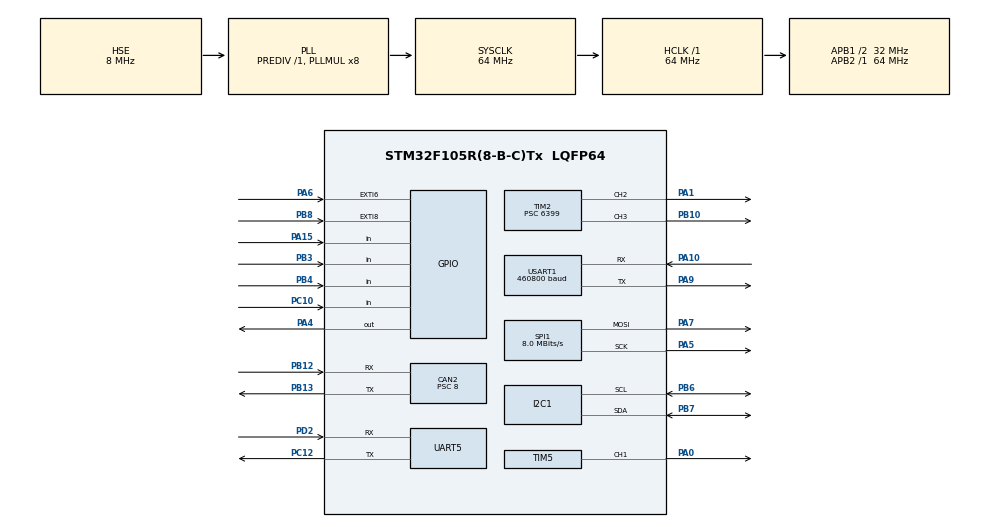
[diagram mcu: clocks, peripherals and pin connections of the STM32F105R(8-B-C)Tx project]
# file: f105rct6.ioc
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CAN2.ABOM=ENABLE
CAN2.BS1=CAN_BS1_13TQ
CAN2.BS2=CAN_BS2_2TQ
CAN2.CalculateBaudRate=250000
CAN2.CalculateTimeBit=4000
CAN2.CalculateTimeQuantum=250.0
CAN2.NART=ENABLE
CAN2.Prescaler=8
Dma.I2C1_RX.0.Direction=DMA_PERIPH_TO_MEMORY
Dma.I2C1_RX.0.Instance=DMA1_Channel7
Dma.I2C1_RX.0.MemDataAlignment=DMA_MDATAALIGN_BYTE
Dma.I2C1_RX.0.MemInc=DMA_MINC_ENABLE
Dma.I2C1_RX.0.Mode=DMA_NORMAL
Dma.I2C1_RX.0.PeriphDataAlignment=DMA_PDATAALIGN_BYTE
Dma.I2C1_RX.0.PeriphInc=DMA_PINC_DISABLE
Dma.I2C1_RX.0.Priority=DMA_PRIORITY_HIGH
Dma.I2C1_TX.1.Direction=DMA_MEMORY_TO_PERIPH
Dma.I2C1_TX.1.Instance=DMA1_Channel6
Dma.I2C1_TX.1.MemDataAlignment=DMA_MDATAALIGN_BYTE
Dma.I2C1_TX.1.MemInc=DMA_MINC_ENABLE
Dma.I2C1_TX.1.Mode=DMA_NORMAL
Dma.I2C1_TX.1.PeriphDataAlignment=DMA_PDATAALIGN_BYTE
Dma.I2C1_TX.1.PeriphInc=DMA_PINC_DISABLE
Dma.I2C1_TX.1.Priority=DMA_PRIORITY_VERY_HIGH
Dma.Request0=I2C1_RX
Dma.Request1=I2C1_TX
Dma.Request2=SPI1_TX
Dma.Request3=USART1_TX
Dma.Request4=USART1_RX
Dma.SPI1_TX.2.Direction=DMA_MEMORY_TO_PERIPH
Dma.SPI1_TX.2.Instance=DMA1_Channel3
Dma.SPI1_TX.2.MemDataAlignment=DMA_MDATAALIGN_BYTE
Dma.SPI1_TX.2.MemInc=DMA_MINC_ENABLE
Dma.SPI1_TX.2.Mode=DMA_NORMAL
Dma.SPI1_TX.2.PeriphDataAlignment=DMA_PDATAALIGN_BYTE
Dma.SPI1_TX.2.PeriphInc=DMA_PINC_DISABLE
Dma.SPI1_TX.2.Priority=DMA_PRIORITY_LOW
Dma.USART1_RX.4.Direction=DMA_PERIPH_TO_MEMORY
Dma.USART1_RX.4.Instance=DMA1_Channel5
Dma.USART1_RX.4.MemDataAlignment=DMA_MDATAALIGN_BYTE
Dma.USART1_RX.4.MemInc=DMA_MINC_ENABLE
Dma.USART1_RX.4.Mode=DMA_NORMAL
Dma.USART1_RX.4.PeriphDataAlignment=DMA_PDATAALIGN_BYTE
Dma.USART1_RX.4.PeriphInc=DMA_PINC_DISABLE
Dma.USART1_RX.4.Priority=DMA_PRIORITY_LOW
Dma.USART1_TX.3.Direction=DMA_MEMORY_TO_PERIPH
Dma.USART1_TX.3.Instance=DMA1_Channel4
Dma.USART1_TX.3.MemDataAlignment=DMA_MDATAALIGN_BYTE
Dma.USART1_TX.3.MemInc=DMA_MINC_ENABLE
Dma.USART1_TX.3.Mode=DMA_NORMAL
Dma.USART1_TX.3.PeriphDataAlignment=DMA_PDATAALIGN_BYTE
Dma.USART1_TX.3.PeriphInc=DMA_PINC_DISABLE
Dma.USART1_TX.3.Priority=DMA_PRIORITY_LOW
FREERTOS.Tasks01=defaultTask,24,1024,StartDefaultTask,Default,NULL,Dynamic,NULL,NULL
FREERTOS.configCHECK_FOR_STACK_OVERFLOW=2
FREERTOS.configENABLE_FPU=1
FREERTOS.configTOTAL_HEAP_SIZE=28000
I2C1.I2C_Mode=I2C_Fast
Mcu.Family=STM32F1
Mcu.Name=STM32F105R(8-B-C)Tx
Mcu.Package=LQFP64
NVIC.CAN2_RX0_IRQn=true\:5\:0\:false\:false\:true\:true\:true\:true\:true
NVIC.CAN2_RX1_IRQn=true\:5\:0\:false\:false\:true\:true\:true\:true\:true
NVIC.CAN2_SCE_IRQn=true\:5\:0\:false\:false\:true\:true\:true\:true\:true
NVIC.CAN2_TX_IRQn=true\:5\:0\:false\:false\:true\:true\:true\:true\:true
NVIC.DMA1_Channel3_IRQn=true\:6\:0\:true\:false\:true\:true\:false\:true\:true
NVIC.DMA1_Channel4_IRQn=true\:5\:0\:false\:false\:true\:true\:false\:true\:true
NVIC.DMA1_Channel5_IRQn=true\:5\:0\:false\:false\:true\:true\:false\:true\:true
NVIC.DMA1_Channel6_IRQn=true\:5\:0\:false\:false\:true\:true\:false\:true\:true
NVIC.DMA1_Channel7_IRQn=true\:5\:0\:false\:false\:true\:true\:false\:true\:true
NVIC.EXTI9_5_IRQn=true\:5\:0\:false\:false\:true\:true\:true\:true\:true
NVIC.I2C1_ER_IRQn=true\:5\:0\:false\:false\:true\:true\:true\:true\:true
NVIC.I2C1_EV_IRQn=true\:5\:0\:false\:false\:true\:true\:true\:true\:true
NVIC.PriorityGroup=NVIC_PRIORITYGROUP_4
NVIC.SPI1_IRQn=true\:5\:0\:false\:false\:true\:true\:true\:true\:true
NVIC.TIM1_UP_IRQn=true\:15\:0\:false\:false\:true\:false\:false\:true\:true
NVIC.TIM2_IRQn=true\:5\:0\:false\:false\:true\:true\:true\:true\:true
NVIC.TIM5_IRQn=true\:5\:0\:false\:false\:true\:true\:true\:true\:true
NVIC.TIM6_IRQn=true\:5\:0\:false\:false\:true\:true\:true\:true\:true
NVIC.TimeBase=TIM1_UP_IRQn
NVIC.TimeBaseIP=TIM1
NVIC.UART5_IRQn=true\:5\:0\:false\:false\:true\:true\:true\:true\:true
NVIC.USART1_IRQn=true\:5\:0\:true\:false\:true\:true\:true\:true\:true
PA0-WKUP.Signal=S_TIM5_CH1
PA1.Signal=S_TIM2_CH2
PA10.GPIO_PuPd=GPIO_PULLUP
PA10.Mode=Asynchronous
PA10.Signal=USART1_RX
PA13.Mode=Serial_Wire
PA13.Signal=SYS_JTMS-SWDIO
PA14.Mode=Serial_Wire
PA14.Signal=SYS_JTCK-SWCLK
PA15.GPIO_PuPd=GPIO_PULLUP
PA15.Signal=GPIO_Input
PA4.Signal=GPIO_Output
PA5.Mode=TX_Only_Simplex_Unidirect_Master
PA5.Signal=SPI1_SCK
PA6.Signal=GPXTI6
PA7.Mode=TX_Only_Simplex_Unidirect_Master
PA7.Signal=SPI1_MOSI
PA9.Mode=Asynchronous
PA9.Signal=USART1_TX
PB10.Signal=S_TIM2_CH3
PB12.Mode=CAN_Activate
PB12.Signal=CAN2_RX
PB13.Mode=CAN_Activate
PB13.Signal=CAN2_TX
PB3.GPIO_PuPd=GPIO_PULLUP
PB3.Signal=GPIO_Input
PB4.GPIO_PuPd=GPIO_PULLUP
PB4.Signal=GPIO_Input
PB6.Mode=I2C
PB6.Signal=I2C1_SCL
PB7.Mode=I2C
PB7.Signal=I2C1_SDA
PB8.Signal=GPXTI8
PC10.GPIO_PuPd=GPIO_PULLUP
PC10.Signal=GPIO_Input
PC12.Mode=Asynchronous
PC12.Signal=UART5_TX
PC14-OSC32_IN.Mode=LSE-External-Oscillator
PC14-OSC32_IN.Signal=RCC_OSC32_IN
PC15-OSC32_OUT.Mode=LSE-External-Oscillator
PC15-OSC32_OUT.Signal=RCC_OSC32_OUT
PD0-OSC_IN.Mode=HSE-External-Oscillator
PD0-OSC_IN.Signal=RCC_OSC_IN
PD1-OSC_OUT.Mode=HSE-External-Oscillator
PD1-OSC_OUT.Signal=RCC_OSC_OUT
PD2.Mode=Asynchronous
PD2.Signal=UART5_RX
ProjectManager.HeapSize=0x200
ProjectManager.StackSize=0x400
ProjectManager.TargetToolchain=CMake
RCC.AHBFreq_Value=64000000
RCC.APB1CLKDivider=RCC_HCLK_DIV2
RCC.APB1Freq_Value=32000000
RCC.APB1TimFreq_Value=64000000
RCC.APB2Freq_Value=64000000
RCC.APB2TimFreq_Value=64000000
RCC.HCLKFreq_Value=64000000
RCC.PLLMUL=RCC_PLL_MUL8
RCC.PLLSourceVirtual=RCC_PLLSOURCE_HSE
RCC.SYSCLKFreq_VALUE=64000000
RCC.SYSCLKSource=RCC_SYSCLKSOURCE_PLLCLK
RCC.USBFreq_Value=42666666.666666664
SH.S_TIM2_CH2.0=TIM2_CH2,PWM Generation2 CH2
SH.S_TIM2_CH3.0=TIM2_CH3,PWM Generation3 CH3
SH.S_TIM5_CH1.0=TIM5_CH1,PWM Generation1 CH1
SPI1.BaudRatePrescaler=SPI_BAUDRATEPRESCALER_8
SPI1.CalculateBaudRate=8.0 MBits/s
SPI1.Direction=SPI_DIRECTION_2LINES
SPI1.Mode=SPI_MODE_MASTER
SPI1.VirtualType=VM_MASTER
TIM2.Channel-PWM\ Generation2\ CH2=TIM_CHANNEL_2
TIM2.Channel-PWM\ Generation3\ CH3=TIM_CHANNEL_3
TIM2.Period=9999
TIM2.Prescaler=6399
TIM2.Pulse-PWM\ Generation2\ CH2=10
TIM2.Pulse-PWM\ Generation3\ CH3=10
TIM5.Channel-PWM\ Generation1\ CH1=TIM_CHANNEL_1
TIM5.Period=3332
TIM5.Prescaler=639
TIM5.Pulse-PWM\ Generation1\ CH1=100
TIM6.Period=19999
TIM6.Prescaler=63
UART5.VirtualMode=Asynchronous
USART1.BaudRate=460800
USART1.VirtualMode=VM_ASYNC
VP_FREERTOS_VS_CMSIS_V2.Mode=CMSIS_V2
VP_SYS_VS_tim1.Mode=TIM1
VP_TIM5_VS_ClockSourceINT.Mode=Internal
VP_TIM6_VS_ClockSourceINT.Mode=Enable_Timer
board=custom

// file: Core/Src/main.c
/* USER CODE BEGIN Header */
/**
  ******************************************************************************
  * @file           : main.c
  * @brief          : Main program body
  ******************************************************************************
  * @attention
  *
  * Copyright (c) 2026 STMicroelectronics.
  * All rights reserved.
  *
  * This software is licensed under terms that can be found in the LICENSE file
  * in the root directory of this software component.
  * If no LICENSE file comes with this software, it is provided AS-IS.
  *
  ******************************************************************************
  */
/* USER CODE END Header */
#include "main.h"
#include "cmsis_os.h"
#include "can.h"
#include "dma.h"
#include "i2c.h"
#include "spi.h"
#include "tim.h"
#include "usart.h"
#include "gpio.h"

/* USER CODE BEGIN Includes */
#include "app_main.h"

/* USER CODE END Includes */

void SystemClock_Config(void);
void MX_FREERTOS_Init(void);
/* USER CODE BEGIN PFP */
void app_on_tim2_period_elapsed(void);
void app_on_tim5_period_elapsed(void);
void app_on_tim6_period_elapsed(void);

/* USER CODE END PFP */

int main(void)
{

  /* MCU Configuration--------------------------------------------------------*/

  /* Reset of all peripherals, Initializes the Flash interface and the Systick. */
  HAL_Init();

  /* Configure the system clock */
  SystemClock_Config();

  /* Initialize all configured peripherals */
  MX_GPIO_Init();
  MX_DMA_Init();
  MX_I2C1_Init();
  MX_SPI1_Init();
  MX_UART5_Init();
  MX_USART1_UART_Init();
  MX_TIM5_Init();
  MX_TIM6_Init();
  MX_TIM2_Init();
  MX_CAN2_Init();

  /* Init scheduler */
  osKernelInitialize();  /* Call init function for freertos objects (in cmsis_os2.c) */
  MX_FREERTOS_Init();

  /* Start scheduler */
  osKernelStart();

  /* We should never get here as control is now taken by the scheduler */

  /* Infinite loop */
  while (1)
  {

  }
}

void SystemClock_Config(void)
{
  RCC_OscInitTypeDef RCC_OscInitStruct = {0};
  RCC_ClkInitTypeDef RCC_ClkInitStruct = {0};

  /** Initializes the RCC Oscillators according to the specified parameters
  * in the RCC_OscInitTypeDef structure.
  */
  RCC_OscInitStruct.OscillatorType = RCC_OSCILLATORTYPE_HSE;
  RCC_OscInitStruct.HSEState = RCC_HSE_ON;
  RCC_OscInitStruct.HSEPredivValue = RCC_HSE_PREDIV_DIV1;
  RCC_OscInitStruct.HSIState = RCC_HSI_ON;
  RCC_OscInitStruct.Prediv1Source = RCC_PREDIV1_SOURCE_HSE;
  RCC_OscInitStruct.PLL.PLLState = RCC_PLL_ON;
  RCC_OscInitStruct.PLL.PLLSource = RCC_PLLSOURCE_HSE;
  RCC_OscInitStruct.PLL.PLLMUL = RCC_PLL_MUL8;
  RCC_OscInitStruct.PLL2.PLL2State = RCC_PLL_NONE;
  if (HAL_RCC_OscConfig(&RCC_OscInitStruct) != HAL_OK)
  {
    Error_Handler();
  }

  /** Initializes the CPU, AHB and APB buses clocks
  */
  RCC_ClkInitStruct.ClockType = RCC_CLOCKTYPE_HCLK|RCC_CLOCKTYPE_SYSCLK
                              |RCC_CLOCKTYPE_PCLK1|RCC_CLOCKTYPE_PCLK2;
  RCC_ClkInitStruct.SYSCLKSource = RCC_SYSCLKSOURCE_PLLCLK;
  RCC_ClkInitStruct.AHBCLKDivider = RCC_SYSCLK_DIV1;
  RCC_ClkInitStruct.APB1CLKDivider = RCC_HCLK_DIV2;
  RCC_ClkInitStruct.APB2CLKDivider = RCC_HCLK_DIV1;

  if (HAL_RCC_ClockConfig(&RCC_ClkInitStruct, FLASH_LATENCY_2) != HAL_OK)
  {
    Error_Handler();
  }

  /** Configure the Systick interrupt time
  */
  __HAL_RCC_PLLI2S_ENABLE();
}

void HAL_TIM_PeriodElapsedCallback(TIM_HandleTypeDef *htim)
{
  if (htim->Instance == TIM1)
  {
    HAL_IncTick();
  }
  /* USER CODE BEGIN Callback 1 */
  else if (htim->Instance == TIM2)
  {
    app_on_tim2_period_elapsed();
  }
  else if (htim->Instance == TIM5)
  {
    app_on_tim5_period_elapsed();
  }
  else if (htim->Instance == TIM6)
  {
    app_on_tim6_period_elapsed();
  }
  /* USER CODE END Callback 1 */
}

void Error_Handler(void)
{
  __disable_irq();
  while (1)
  {
  }
}

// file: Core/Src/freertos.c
/* USER CODE BEGIN Header */
/**
  ******************************************************************************
  * File Name          : freertos.c
  * Description        : Code for freertos applications
  ******************************************************************************
  * @attention
  *
  * Copyright (c) 2026 STMicroelectronics.
  * All rights reserved.
  *
  * This software is licensed under terms that can be found in the LICENSE file
  * in the root directory of this software component.
  * If no LICENSE file comes with this software, it is provided AS-IS.
  *
  ******************************************************************************
  */
/* USER CODE END Header */

#include "FreeRTOS.h"
#include "task.h"
#include "main.h"
#include "cmsis_os.h"

/* USER CODE BEGIN Includes */
#include "app_main.h"

/* USER CODE END Includes */

/* Definitions for defaultTask */
osThreadId_t defaultTaskHandle;
const osThreadAttr_t defaultTask_attributes = {
  .name = "defaultTask",
  .stack_size = 1024 * 4,
  .priority = (osPriority_t) osPriorityNormal,
};

void StartDefaultTask(void *argument);

void MX_FREERTOS_Init(void); /* (MISRA C 2004 rule 8.1) */

/* Hook prototypes */
void vApplicationStackOverflowHook(xTaskHandle xTask, signed char *pcTaskName);

/* USER CODE BEGIN 4 */
void vApplicationStackOverflowHook(xTaskHandle xTask, signed char *pcTaskName)
{
   /* Run time stack overflow checking is performed if
   configCHECK_FOR_STACK_OVERFLOW is defined to 1 or 2. This hook function is
   called if a stack overflow is detected. */
  (void)xTask;
  (void)pcTaskName;
}
/* USER CODE END 4 */

void MX_FREERTOS_Init(void) {

  /* Create the thread(s) */
  /* creation of defaultTask */
  defaultTaskHandle = osThreadNew(StartDefaultTask, NULL, &defaultTask_attributes);

}

void StartDefaultTask(void *argument)
{
  /* USER CODE BEGIN StartDefaultTask */
  app_main();
  /* Infinite loop */
  for(;;)
  {
    osDelay(1);
  }
  /* USER CODE END StartDefaultTask */
}
